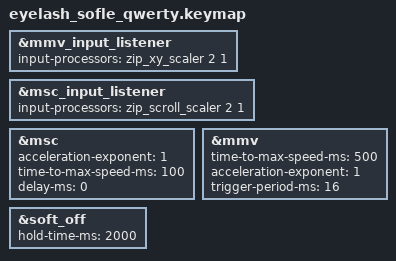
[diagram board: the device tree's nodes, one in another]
// Miryoku QWERTY layout for eyelash_sofle
// This is the fallback layout - QWERTY alphas with Miryoku layers
#define MIRYOKU_ALPHAS_QWERTY
#include "miryoku/custom_config.h"
#include "miryoku/eyelash_sofle.h"
#include "../../../miryoku_zmk/miryoku/miryoku.dtsi"

#define ZMK_POINTING_DEFAULT_MOVE_VAL 1200
#define ZMK_POINTING_DEFAULT_SCRL_VAL 25

#include <input/processors.dtsi>
#include <zephyr/dt-bindings/input/input-event-codes.h>
#include <behaviors.dtsi>
#include <dt-bindings/zmk/bt.h>
#include <dt-bindings/zmk/keys.h>
#include <dt-bindings/zmk/outputs.h>
#include <dt-bindings/zmk/pointing.h>
#include <dt-bindings/zmk/rgb.h>

&mmv_input_listener { input-processors = <&zip_xy_scaler 2 1>; };
&msc_input_listener { input-processors = <&zip_scroll_scaler 2 1>; };

&msc {
    acceleration-exponent = <1>;
    time-to-max-speed-ms = <100>;
    delay-ms = <0>;
};

&mmv {
    time-to-max-speed-ms = <500>;
    acceleration-exponent = <1>;
    trigger-period-ms = <16>;
};

&soft_off { hold-time-ms = <2000>; };
